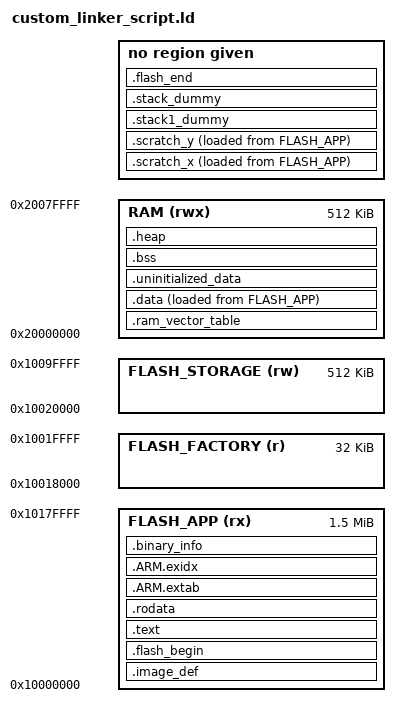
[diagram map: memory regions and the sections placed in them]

/* RP2350 custom linker script */

MEMORY
{
    FLASH_APP (rx)          : ORIGIN = 0x10000000, LENGTH = 1536K    /* 1.5 MB */
    FLASH_FACTORY (r)       : ORIGIN = 0x10018000, LENGTH = 32K      /* 32 KB factory settings */
    FLASH_STORAGE (rw)      : ORIGIN = 0x10020000, LENGTH = 512K     /* 512 KB user data */

    RAM (rwx)               : ORIGIN = 0x20000000, LENGTH = 512K    /* RAM */

}

ENTRY(_entry_point)

SECTIONS
{
    /* Put IMAGE_DEF and any small headers in the first 4KB */
    .image_def : {
        KEEP(*(.image_def))
    } > FLASH_APP

    .flash_begin : {
        __flash_binary_start = .;
    } > FLASH_APP

    
    .text : {
        __logical_binary_start = .;
        KEEP (*(.vectors))
        KEEP (*(.reset))
        KEEP(*(.binary_info_header))
        __binary_info_header_end = .;
        /* TODO revisit this now memset/memcpy/float in ROM */
        /* bit of a hack right now to exclude all floating point and time critical (e.g. memset, memcpy) code from
         * FLASH ... we will include any thing excluded here in .data below by default */
        *(.init)
        *(EXCLUDE_FILE(*libgcc.a: *libc.a:*lib_a-mem*.o *libm.a:) .text*)
        *(.fini)
        /* Pull all c'tors into .text */
        *crtbegin.o(.ctors)
        *crtbegin?.o(.ctors)
        *(EXCLUDE_FILE(*crtend?.o *crtend.o) .ctors)
        *(SORT(.ctors.*))
        *(.ctors)
        /* Followed by destructors */
        *crtbegin.o(.dtors)
        *crtbegin?.o(.dtors)
        *(EXCLUDE_FILE(*crtend?.o *crtend.o) .dtors)
        *(SORT(.dtors.*))
        *(.dtors)

        *(.eh_frame*)
        . = ALIGN(4);
    } > FLASH_APP

    .rodata : {
        *(EXCLUDE_FILE(*libgcc.a: *libc.a:*lib_a-mem*.o *libm.a:) .rodata*)
        . = ALIGN(4);
        *(SORT_BY_ALIGNMENT(SORT_BY_NAME(.flashdata*)))
        . = ALIGN(4);
    } > FLASH_APP

    .ARM.extab :
    {
        *(.ARM.extab* .gnu.linkonce.armextab.*)
    } > FLASH_APP

    __exidx_start = .;
    .ARM.exidx :
    {
        *(.ARM.exidx* .gnu.linkonce.armexidx.*)
    } > FLASH_APP
    __exidx_end = .;

    /* Machine inspectable binary information */
    . = ALIGN(4);
    __binary_info_start = .;
    .binary_info :
    {
        KEEP(*(.binary_info.keep.*))
        *(.binary_info.*)
    } > FLASH_APP
    __binary_info_end = .;
    . = ALIGN(4);

    /* End of .text-like segments */
    __etext = .;


   .ram_vector_table (COPY): {
        *(.ram_vector_table)
    } > RAM

    .data : {
        __data_start__ = .;
        *(vtable)

        *(.time_critical*)

        /* remaining .text and .rodata; i.e. stuff we exclude above because we want it in RAM */
        *(.text*)
        . = ALIGN(4);
        *(.rodata*)
        . = ALIGN(4);

        *(.data*)

        . = ALIGN(4);
        *(.after_data.*)
        . = ALIGN(4);
        /* preinit data */
        PROVIDE_HIDDEN (__mutex_array_start = .);
        KEEP(*(SORT(.mutex_array.*)))
        KEEP(*(.mutex_array))
        PROVIDE_HIDDEN (__mutex_array_end = .);

        . = ALIGN(4);
        /* preinit data */
        PROVIDE_HIDDEN (__preinit_array_start = .); 
        KEEP(*(SORT(.preinit_array.*)))
        KEEP(*(.preinit_array))
        PROVIDE_HIDDEN (__preinit_array_end = .);

        . = ALIGN(4);
        /* init data */
        PROVIDE_HIDDEN (__init_array_start = .);
        KEEP(*(SORT(.init_array.*)))
        KEEP(*(.init_array))
        PROVIDE_HIDDEN (__init_array_end = .);

        . = ALIGN(4);
        /* finit data */
        PROVIDE_HIDDEN (__fini_array_start = .);
        *(SORT(.fini_array.*))
        *(.fini_array)
        PROVIDE_HIDDEN (__fini_array_end = .);

        *(.jcr)
        . = ALIGN(4);
        /* All data end */
        __data_end__ = .;
    } > RAM AT> FLASH_APP

    .uninitialized_data (COPY): {
        . = ALIGN(4);
        *(.uninitialized_data*)
    } > RAM

    /* Start and end symbols must be word-aligned */
    .scratch_x : {
        __scratch_x_start__ = .;
        *(.scratch_x.*)
        . = ALIGN(4);
        __scratch_x_end__ = .;
    } > SCRATCH_X AT > FLASH_APP
    __scratch_x_source__ = LOADADDR(.scratch_x);

    .scratch_y : {
        __scratch_y_start__ = .;
        *(.scratch_y.*)
        . = ALIGN(4);
        __scratch_y_end__ = .;
    } > SCRATCH_Y AT > FLASH_APP
    __scratch_y_source__ = LOADADDR(.scratch_y);

    .bss  : {
        . = ALIGN(4);
        __bss_start__ = .;
        *(SORT_BY_ALIGNMENT(SORT_BY_NAME(.bss*)))
        *(COMMON)
        . = ALIGN(4);
        __bss_end__ = .;
    } > RAM

    .heap (COPY):
    {
        __end__ = .;
        end = __end__;
        *(.heap*)
        __HeapLimit = .;
    } > RAM

    /* .stack*_dummy section doesn't contains any symbols. It is only
     * used for linker to calculate size of stack sections, and assign
     * values to stack symbols later
     *
     * stack1 section may be empty/missing if platform_launch_core1 is not used */

    /* by default we put core 0 stack at the end of scratch Y, so that if core 1
     * stack is not used then all of SCRATCH_X is free.
     */
    .stack1_dummy (COPY):
    {
        *(.stack1*)
    } > SCRATCH_X
    .stack_dummy (COPY):
    {
        *(.stack*)
    } > SCRATCH_Y

    .flash_end : {
        __flash_binary_end = .;
    } > FLASH


    /* stack limit is poorly named, but historically is maximum heap ptr */
    PROVIDE(__StackLimit = ORIGIN(RAM) + LENGTH(RAM));
    PROVIDE(__StackOneTop = ORIGIN(SCRATCH_X) + LENGTH(SCRATCH_X));
    PROVIDE(__StackTop = ORIGIN(SCRATCH_Y) + LENGTH(SCRATCH_Y));
    PROVIDE(__StackOneBottom = __StackOneTop - SIZEOF(.stack1_dummy));
    PROVIDE(__StackBottom = __StackTop - SIZEOF(.stack_dummy));
    PROVIDE(__stack = __StackTop);

    /* Check if data + heap + stack exceeds RAM limit */
    ASSERT(__StackLimit >= __HeapLimit, "region RAM overflowed")

    /* todo assert on extra code */
}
